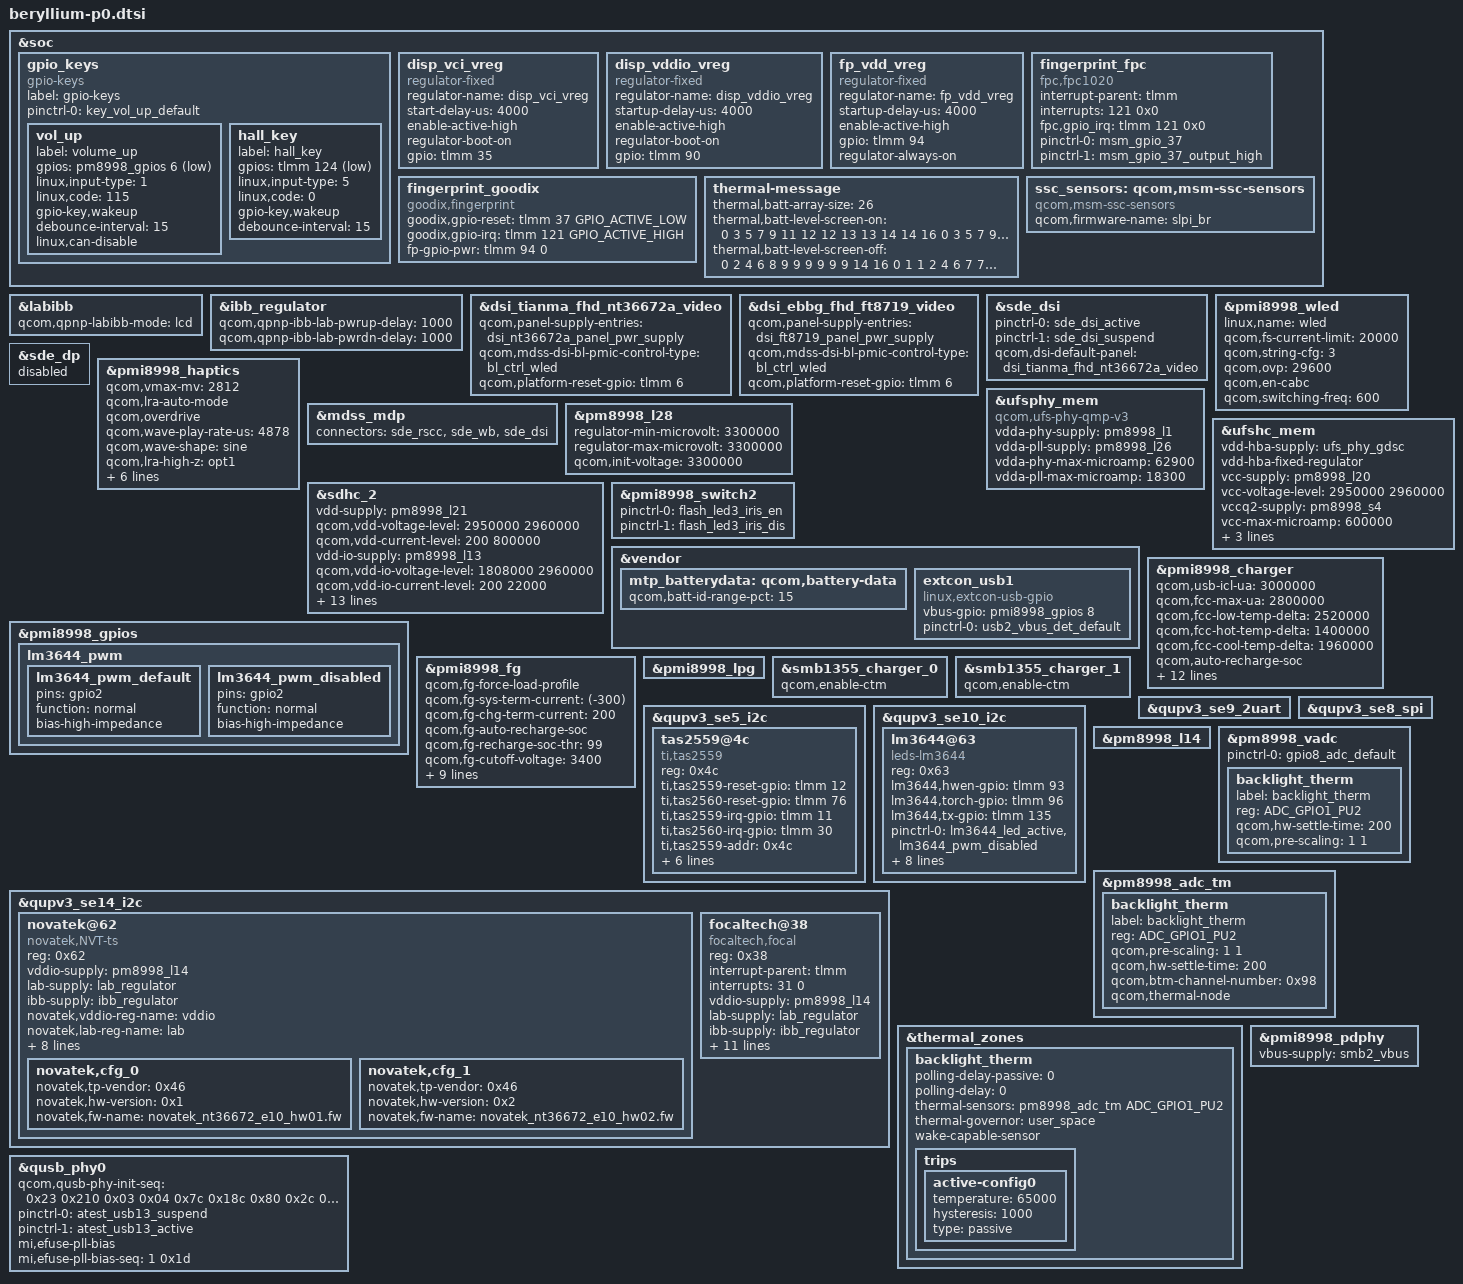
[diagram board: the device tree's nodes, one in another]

/* Copyright (c) 2016-2017, The Linux Foundation. All rights reserved.
 * Copyright (C) 2019 XiaoMi, Inc.
 *
 * This program is free software; you can redistribute it and/or modify
 * it under the terms of the GNU General Public License version 2 and
 * only version 2 as published by the Free Software Foundation.
 *
 * This program is distributed in the hope that it will be useful,
 * but WITHOUT ANY WARRANTY; without even the implied warranty of
 * MERCHANTABILITY or FITNESS FOR A PARTICULAR PURPOSE.  See the
 * GNU General Public License for more details.
 */

#include <dt-bindings/gpio/gpio.h>
#include "../../qcom/sdm845-pmic-overlay.dtsi"
#include "../../qcom/sdm845-pinctrl-overlay.dtsi"
#include "beryllium-p0-camera-sensor-mtp.dtsi"

/* Xiaomi-common */
#include "../common/base_dts/sdm845.dtsi"
#include "../common/base_overlay/sdm845-pmic-overlay.dtsi"
#include "../common/xiaomi_common.dtsi"
#include "../common/xiaomi-common-sde-display.dtsi"

&soc {
	gpio_keys {
		compatible = "gpio-keys";
		label = "gpio-keys";

		pinctrl-names = "default";
		pinctrl-0 = <&key_vol_up_default>;

		vol_up {
			label = "volume_up";
			gpios = <&pm8998_gpios 6 GPIO_ACTIVE_LOW>;
			linux,input-type = <1>;
			linux,code = <115>;
			gpio-key,wakeup;
			debounce-interval = <15>;
			linux,can-disable;
		};
		hall_key {
			label = "hall_key";
			gpios = <&tlmm 124 GPIO_ACTIVE_LOW>;
			linux,input-type = <5>;
			linux,code = <0>;
			gpio-key,wakeup;
			debounce-interval = <15>;
		};
	};
	disp_vci_vreg: disp_vci_vreg {
		compatible = "regulator-fixed";
		regulator-name = "disp_vci_vreg";
		start-delay-us = <4000>;
		enable-active-high;
		regulator-boot-on;
		gpio = <&tlmm 35 0>;
	};

	disp_vddio_vreg: disp_vddio_vreg {
		compatible = "regulator-fixed";
		regulator-name = "disp_vddio_vreg";
		startup-delay-us = <4000>;
		enable-active-high;
		regulator-boot-on;
		gpio = <&tlmm 90 0>;
	 };

	fp_vdd_vreg: fp_vdd_vreg {
		compatible = "regulator-fixed";
		regulator-name = "fp_vdd_vreg";
		startup-delay-us = <4000>;
		enable-active-high;
		gpio = <&tlmm 94 0>;
		regulator-always-on;
	};

	fingerprint_fpc {
		status = "ok";
		compatible = "fpc,fpc1020";
		interrupt-parent = <&tlmm>;
		interrupts = <121 0x0>;
		fpc,gpio_irq    = <&tlmm 121 0x0>;
		/* fpc,enable-on-boot; */
		/* fpc,enable-wakeup;  */

		pinctrl-names = "fpc1020_reset_reset",
			"fpc1020_reset_active";

		pinctrl-0 = <&msm_gpio_37>;
		pinctrl-1 = <&msm_gpio_37_output_high>;
	};

	fingerprint_goodix {
		compatible = "goodix,fingerprint";
		goodix,gpio-reset = <&tlmm 37 GPIO_ACTIVE_LOW>;
		goodix,gpio-irq = <&tlmm 121 GPIO_ACTIVE_HIGH>;
		fp-gpio-pwr = <&tlmm 94 0>;
		status = "ok";
	};

	thermal-message {
		thermal,batt-array-size = "26";
		thermal,batt-level-screen-on = "0 3 5 7 9 11 12 12 13 13 14 14 16 0 3 5 7 9 10 11 12 12 13 14 14 16";
		thermal,batt-level-screen-off = "0 2 4 6 8 9 9 9 9 9 9 14 16 0 1 1 2 4 6 7 7 7 8 9 14 16";
	};
};

&labibb {
	status = "ok";
	qcom,qpnp-labibb-mode = "lcd";
};

&ibb_regulator {
	qcom,qpnp-ibb-lab-pwrup-delay = <1000>;
	qcom,qpnp-ibb-lab-pwrdn-delay = <1000>;
};

&dsi_tianma_fhd_nt36672a_video {
	qcom,panel-supply-entries = <&dsi_nt36672a_panel_pwr_supply>;
	qcom,mdss-dsi-bl-pmic-control-type = "bl_ctrl_wled";
	qcom,platform-reset-gpio = <&tlmm 6 0>;
};

&dsi_ebbg_fhd_ft8719_video {
	qcom,panel-supply-entries = <&dsi_ft8719_panel_pwr_supply>;
	qcom,mdss-dsi-bl-pmic-control-type = "bl_ctrl_wled";
	qcom,platform-reset-gpio = <&tlmm 6 0>;
};

&sde_dsi {
	/delete-property/ qcom,platform-te-gpio;
	pinctrl-0 = <&sde_dsi_active>;
	pinctrl-1 = <&sde_dsi_suspend>;
	qcom,dsi-default-panel = <&dsi_tianma_fhd_nt36672a_video>;
};

&pmi8998_wled {
	status = "okay";
	linux,name = "wled";
	qcom,fs-current-limit = <20000>;
	qcom,string-cfg = <3>;
	qcom,ovp = <29600>;
	qcom,en-cabc;
	qcom,switching-freq = <600>;
};

&sde_dp {
	status = "disabled";
};

&pmi8998_haptics {
	qcom,vmax-mv = <2812>;
	qcom,lra-auto-mode;
	qcom,overdrive;
	qcom,wave-play-rate-us = <4878>;
	qcom,wave-shape = "sine";
	qcom,lra-high-z = "opt1";
	qcom,lra-auto-res-mode = "qwd";
	qcom,lra-res-cal-period = <4>;
	qcom,effect-max = <3>;
	qcom,effect-arry = [3e 3e be a0 00 00 00 00
			3e 3e 3e be be 00 00 00
			3e 3e 3e 3e be be a0 90];
	qcom,play-mode = "direct";
	status = "okay";
};

&mdss_mdp {
	#cooling-cells = <2>;
	connectors = <&sde_rscc &sde_wb &sde_dsi>;
};

&pm8998_l28{
	regulator-min-microvolt = <3300000>;
	regulator-max-microvolt = <3300000>;
	qcom,init-voltage = <3300000>;
};

&ufsphy_mem {
	compatible = "qcom,ufs-phy-qmp-v3";

	vdda-phy-supply = <&pm8998_l1>; /* 0.88v */
	vdda-pll-supply = <&pm8998_l26>; /* 1.2v */
	vdda-phy-max-microamp = <62900>;
	vdda-pll-max-microamp = <18300>;

	status = "ok";
};

&ufshc_mem {
	vdd-hba-supply = <&ufs_phy_gdsc>;
	vdd-hba-fixed-regulator;
	vcc-supply = <&pm8998_l20>;
	vcc-voltage-level = <2950000 2960000>;
	vccq2-supply = <&pm8998_s4>;
	vcc-max-microamp = <600000>;
	vccq2-max-microamp = <600000>;

	qcom,vddp-ref-clk-supply = <&pm8998_l2>;
	qcom,vddp-ref-clk-max-microamp = <100>;

	status = "ok";
};

&sdhc_2 {
	vdd-supply = <&pm8998_l21>;
	qcom,vdd-voltage-level = <2950000 2960000>;
	qcom,vdd-current-level = <200 800000>;

	vdd-io-supply = <&pm8998_l13>;
	qcom,vdd-io-voltage-level = <1808000 2960000>;
	qcom,vdd-io-current-level = <200 22000>;

	pinctrl-names = "active", "sleep", "ds_400KHz",
			"ds_50MHz", "ds_100MHz", "ds_200MHz";
	pinctrl-0 = <&sdc2_clk_on  &sdc2_cmd_on &sdc2_data_on &storage_cd>;
	pinctrl-1 = <&sdc2_clk_off &sdc2_cmd_off &sdc2_data_off &storage_cd>;
	pinctrl-2 = <&sdc2_clk_ds_400KHz
			&sdc2_cmd_ds_400KHz &sdc2_data_ds_400KHz>;
	pinctrl-3 = <&sdc2_clk_ds_50MHz
			&sdc2_cmd_ds_50MHz &sdc2_data_ds_50MHz>;
	pinctrl-4 = <&sdc2_clk_ds_100MHz
			&sdc2_cmd_ds_100MHz &sdc2_data_ds_100MHz>;
	pinctrl-5 = <&sdc2_clk_ds_200MHz
			&sdc2_cmd_ds_200MHz &sdc2_data_ds_200MHz>;

	cd-gpios = <&tlmm 126 GPIO_ACTIVE_HIGH>;

	status = "ok";
};

&pmi8998_switch2 {
	pinctrl-names = "led_enable", "led_disable";
	pinctrl-0 = <&flash_led3_iris_en>;
	pinctrl-1 = <&flash_led3_iris_dis>;
};

&vendor{
	mtp_batterydata: qcom,battery-data {
		qcom,batt-id-range-pct = <15>;
		#include "battery/batterydata-e10-atl-4000mAh.dtsi"
		#include "battery/batterydata-e10-cos-4000mAh.dtsi"
	};

	extcon_usb1: extcon_usb1 {
		compatible = "linux,extcon-usb-gpio";
		vbus-gpio = <&pmi8998_gpios 8 GPIO_ACTIVE_HIGH>;

		pinctrl-names = "default";
		pinctrl-0 = <&usb2_vbus_det_default>;
	};
};

&pmi8998_gpios {
	lm3644_pwm {
		lm3644_pwm_default: lm3644_pwm_default {
				pins = "gpio2";
				function = "normal";
				bias-high-impedance;
		};

		lm3644_pwm_disabled: lm3644_pwm_disabled {
				pins = "gpio2";
				function = "normal";
				bias-high-impedance;
		};
	};
};

&pmi8998_charger {
	qcom,usb-icl-ua = <3000000>;
	qcom,fcc-max-ua = <2800000>;
	qcom,fcc-low-temp-delta = <2520000>;
	qcom,fcc-hot-temp-delta = <1400000>;
	qcom,fcc-cool-temp-delta = <1960000>;
	qcom,auto-recharge-soc;
	qcom,sw-jeita-enable;
	qcom,dynamic-fv-enable;
	qcom,thermal-mitigation
				= <1800000 1600000 1400000 1200000 1000000 1000000 1000000>;
	qcom,thermal-mitigation-dcp
				= <1800000 1800000 1800000 1800000 1800000 1800000 1800000
				   1800000 1800000 1800000 1800000 1800000 1600000 1400000
				   1200000 1000000>;
	qcom,thermal-mitigation-qc3
				= <3000000 2725000 2575000 2425000 2275000 2125000 2000000
				   1800000 1650000 1500000 1360000 1200000 1060000 900000
				   752500 525000>;
	qcom,thermal-mitigation-qc2
				= <1625000 1625000 1625000 1625000 1625000 1525000 1425000
				   1325000 1225000 1125000 10255000 925000 825000 725000
				   625000 525000>;
	qcom,thermal-mitigation-pd-base
				= <3000000 2800000 2600000 2400000 2200000 2000000 1800000
				1600000 1600000 1400000 1200000 1100000 1000000 900000
				752500 525000>;
};

&pmi8998_fg {
	qcom,fg-force-load-profile;
	qcom,fg-sys-term-current = <(-300)>;
	qcom,fg-chg-term-current = <200>;
	qcom,fg-auto-recharge-soc;
	qcom,fg-recharge-soc-thr = <99>;
	qcom,fg-cutoff-voltage = <3400>;
	qcom,fg-cutoff-current = <200>;
	qcom,fg-empty-voltage = <3100>;
	qcom,fg-jeita-hyst-temp = <2>;
	qcom,fg-jeita-thresholds = <0 15 45 60>;
	qcom,fg-esr-clamp-mohms = <60>;
	qcom,fg-batt-temp-delta = <6>;
	qcom,battery-data = <&mtp_batterydata>;
	qcom,slope-limit-temp-threshold = <100>;
	qcom,slope-limit-coeffs = <10 11 12 13>;
};

&pmi8998_lpg {
	status = "okay";
};

&smb1355_charger_0 {
	status = "ok";
	qcom,enable-ctm;
};

&smb1355_charger_1 {
	status = "ok";
	qcom,enable-ctm;
};

&qupv3_se9_2uart {
	status = "ok";
};

&qupv3_se8_spi {
	status = "ok";
};

&qupv3_se5_i2c {
	status = "ok";
	/*smart PA*/
	tas2559@4c{
		compatible = "ti,tas2559";
		reg = <0x4c>;
		ti,tas2559-reset-gpio = <&tlmm 12 0>;
		ti,tas2560-reset-gpio = <&tlmm 76 0>;
		ti,tas2559-irq-gpio = <&tlmm 11 0>;
		ti,tas2560-irq-gpio = <&tlmm 30 0>;
		ti,tas2559-addr = <0x4c>;
		ti,tas2560-addr = <0x4d>;
		ti,tas2559-channel = <0>; /* 0, left; 1, right */
		ti,tas2560-channel = <1>; /* 0, left; 1, right */
		ti,ycrc-enable = <0>;           /* 0, disable; non-zero, enable */
		ti,echo-ref = <0>;              /* 0, left channel; 1, right channel; 2, both */
		ti,bit-rate = <16>;             /* 16, 20, 24, 32 */
		status = "ok";
	};

};

&qupv3_se10_i2c {
	status = "ok";
	lm3644@63 {
		compatible = "leds-lm3644";
		reg = <0x63>;
		lm3644,hwen-gpio = <&tlmm 93 0x00>;
		lm3644,torch-gpio = <&tlmm 96 0x00>;
		lm3644,tx-gpio = <&tlmm 135 0x00>;
		pinctrl-names = "lm3644_led_active", "lm3644_led_active_pwm", "lm3644_led_suspend";
		pinctrl-0 = <&lm3644_led_active &lm3644_pwm_disabled>;
		pinctrl-1 = <&lm3644_led_active &lm3644_pwm_default>;
		pinctrl-2 = <&lm3644_led_suspend &lm3644_pwm_disabled>;

		lm3644,use-simulative-pwm;
		pwms = <&pmi8998_lpg 1 25000>;
		lm3644,period-us = <25000>;
		lm3644,duty-us = <2500>;
	};
};

&qupv3_se14_i2c {
	status = "ok";
	/* Novatek device tree node */
	novatek@62 {
		compatible = "novatek,NVT-ts";
		reg = <0x62>;
		status = "ok";

		vddio-supply = <&pm8998_l14>;
		/*avdd-supply = <&pm8994_l22>;*/
		lab-supply = <&lab_regulator>;
		ibb-supply = <&ibb_regulator>;
		novatek,vddio-reg-name = "vddio";
		novatek,lab-reg-name = "lab";
		novatek,ibb-reg-name = "ibb";

		novatek,reset-tddi = <&tlmm 6 0x00>;
		novatek,reset-gpio = <&tlmm 32 0x00>;
		novatek,irq-gpio = <&tlmm 31 0x2001>;
		pinctrl-names = "pmx_ts_active", "pmx_ts_suspend";
		pinctrl-0 = <&ts_int_active_br &ts_reset_active_br>;
		pinctrl-1 = <&ts_int_suspend &ts_reset_suspend>;
		novatek,config-array-size = <2>;
		novatek,cfg_0 {
			novatek,tp-vendor = <0x46>;
			novatek,hw-version = <0x1>;
			novatek,fw-name = "novatek_nt36672_e10_hw01.fw";
		};
		novatek,cfg_1 {
			novatek,tp-vendor = <0x46>;
			novatek,hw-version = <0x2>;
			novatek,fw-name = "novatek_nt36672_e10_hw02.fw";
		};

		/* MP */
		/*novatek,mp-support-dt;*/
	};

	focaltech@38 {
		compatible = "focaltech,focal";
		reg = <0x38>;
		interrupt-parent = <&tlmm>;
		interrupts = <31 0>;
		vddio-supply = <&pm8998_l14>;
		/*avdd-supply = <&pm8994_l22>;*/
		lab-supply = <&lab_regulator>;
		ibb-supply = <&ibb_regulator>;

		focaltech,reset-gpio = <&tlmm 32 0x01>;
		focaltech,irq-gpio = <&tlmm 31 0x02>;
		focaltech,max-touch-number = <10>;
		focaltech,display-coords = <0 0 1080 2246>;
		focaltech,project-name = "e10";
		focaltech,lockdown-info-addr = <0x1FA0>;
		focaltech,timeout-read-reg = <1000>;
		focaltech,cutoff-power;
		pinctrl-names = "pmx_ts_active", "pmx_ts_suspend";
		pinctrl-0 = <&ts_int_active_br &ts_reset_active_br>;
		pinctrl-1 = <&ts_int_suspend &ts_reset_suspend>;
		/* focaltech,have-key; */
	};
};

&pm8998_l14 {
	//regulator-boot-on;
};

&pm8998_vadc {
	pinctrl-names = "default";
	pinctrl-0 = <&gpio8_adc_default>;

	backlight_therm {
		label = "backlight_therm";
		reg = <ADC_GPIO1_PU2>;
		qcom,hw-settle-time = <200>;
		qcom,pre-scaling = <1 1>;
	};
};

&pm8998_adc_tm {
	backlight_therm {
		label = "backlight_therm";
		reg = <ADC_GPIO1_PU2>;
		qcom,pre-scaling = <1 1>;
		qcom,hw-settle-time = <200>;
		qcom,btm-channel-number = <0x98>;
		qcom,thermal-node;
	};
};

&thermal_zones {
	backlight_therm {
		polling-delay-passive = <0>;
		polling-delay = <0>;
		thermal-sensors = <&pm8998_adc_tm ADC_GPIO1_PU2>;
		thermal-governor = "user_space";
		wake-capable-sensor;

		trips {
			active-config0 {
				temperature = <65000>;
				hysteresis = <1000>;
				type = "passive";
			};
		};
	};
};

&qusb_phy0 {
		qcom,qusb-phy-init-seq =
			/* <value reg_offset> */
			   <0x23 0x210 /* PWR_CTRL1 */
			    0x03 0x04  /* PLL_ANALOG_CONTROLS_TWO */
			    0x7c 0x18c /* PLL_CLOCK_INVERTERS */
			    0x80 0x2c  /* PLL_CMODE */
			    0x0a 0x184 /* PLL_LOCK_DELAY */
			    0x19 0xb4  /* PLL_DIGITAL_TIMERS_TWO */
			    0x40 0x194 /* PLL_BIAS_CONTROL_1 */
			    0x18 0x198 /* PLL_BIAS_CONTROL_2 */
			    0x21 0x214 /* PWR_CTRL2 */
			    0x08 0x220 /* IMP_CTRL1 */
			    0x58 0x224 /* IMP_CTRL2 */
			    0x07 0x240 /* TUNE1 */
			    0x29 0x244 /* TUNE2 */
			    0xca 0x248 /* TUNE3 */
			    0x04 0x24c /* TUNE4 */
			    0x03 0x250 /* TUNE5 */
			    0x00 0x23c /* CHG_CTRL2 */
			    0x22 0x210>; /* PWR_CTRL1 */
	pinctrl-names = "atest_usb13_suspend","atest_usb13_active";
	pinctrl-0 = <&atest_usb13_suspend>;
	pinctrl-1 = <&atest_usb13_active>;
	mi,efuse-pll-bias;
	mi,efuse-pll-bias-seq = <1 0x1d>;
};

&pmi8998_pdphy {
	vbus-supply = <&smb2_vbus>;
};

&soc {
	ssc_sensors: qcom,msm-ssc-sensors {
		compatible = "qcom,msm-ssc-sensors";
		status = "ok";
		qcom,firmware-name = "slpi_br";
	};
};
